AUTOSAR XML (schema 314)
package /ComponentType
  internal behavior Sa_MtrPosDiag_InternalBehavior: component=Sa_MtrPosDiag
    timing event TMT_MtrPosDiag_Per1: start-on-event=MtrPosDiag_Per1, period=0.002
    timing event TMT_MtrPosDiag_Per2: start-on-event=MtrPosDiag_Per2, period=0.002
    port-api-options:
      enable-take-address=false, indirect-api=false, port=Cos1RTOffset
      enable-take-address=false, indirect-api=false, port=MtrPos
      enable-take-address=false, indirect-api=false, port=MtrPosMech
      enable-take-address=false, indirect-api=false, port=MtrPosMech2
      enable-take-address=false, indirect-api=false, port=NxtrDiagMgr
      enable-take-address=false, indirect-api=false, port=Sin1RTOffset
    runnable MtrPosDiag_Per1
      data read access READ_Cos1RTOffset_Volts_f32: data-element=Cos1RTOffset.Volts_f32
      data read access READ_Sin1RTOffset_Volts_f32: data-element=Sin1RTOffset.Volts_f32
      sync call SC_MtrPos_CosTheta1_V_f32: operation=MtrPos.CosTheta1_V_f32, timeout=0
      sync call SC_MtrPos_SinTheta1_V_f32: operation=MtrPos.SinTheta1_V_f32, timeout=0
      sync call SC_NxtrDiagMgr_SetNTCStatus: operation=NxtrDiagMgr.SetNTCStatus, timeout=0
    runnable MtrPosDiag_Per2
      data read access READ_MtrPosMech_Rev_f32: data-element=MtrPosMech.Rev_f32
      data read access READ_MtrPosMech2_Rev_f32: data-element=MtrPosMech2.Rev_f32
      sync call SC_NxtrDiagMgr_SetNTCStatus: operation=NxtrDiagMgr.SetNTCStatus, timeout=0
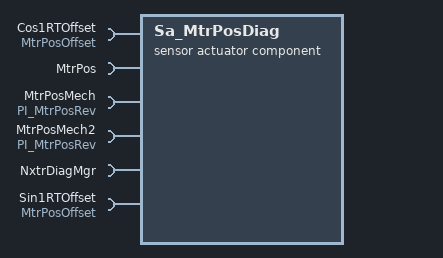
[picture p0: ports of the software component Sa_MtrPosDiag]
  sensor actuator software component type Sa_MtrPosDiag
    6 x require port:
      Cos1RTOffset: unqueued-receiver-com-spec{data-element=Volts_f32, init-value=D_FLOATZERO_ULS_F32}, required-interface=MtrPosOffset
      MtrPos: required-com-specs=[CosTheta1_V_f32, InvCosTheta2_V_f32, InvSinTheta2_V_f32, SinTheta1_V_f32], required-interface=MtrPos
      MtrPosMech: unqueued-receiver-com-spec{data-element=Rev_f32, init-value=D_FLOATZERO_ULS_F32}, required-interface=PI_MtrPosRev
      MtrPosMech2: unqueued-receiver-com-spec{data-element=Rev_f32, init-value=D_FLOATZERO_ULS_F32}, required-interface=PI_MtrPosRev
      NxtrDiagMgr: required-com-specs=[GetNTCFailed, GetNTCStatus, ResetEventStatus, SetNTCStatus, SetOperationCycleState], required-interface=NxtrDiagMgr
      Sin1RTOffset: unqueued-receiver-com-spec{data-element=Volts_f32, init-value=D_FLOATZERO_ULS_F32}, required-interface=MtrPosOffset
  swc implementation Sa_MtrPosDiag_Implementation: behavior=Sa_MtrPosDiag_InternalBehavior
    code-descriptors:
      code Code: type=SRC
